# nrf9220_celldsp register map
Vendor: Nordic Semiconductor; Series: nRF92; File version: 1
Registers are 32-bit, read-write, reset 0x0 unless marked. A register's access mark holds for its fields unless they carry their own. Offsets are from the block's base; [hi:lo] are bit positions; {n}, {i} and the like mark numbered series.

## TRACEDELAYREG — Trace delay register
Base 0x45027000
0x504 DELAYREGCONFIG — Configuration register for DELAYREG delay
  [4:0] DELAYREGCONFIG — Register write delay, configurable between 0 and 31 clock cycles. Delay between apbPEnable and apbPReady is adjusted to the configured value, except for the small values, when minimum interconnect delay exist.
0x600 DELAYREG wo — Dummy register with adjustable write delay. Occupies 0x100 address range i.e. 256bytes. This space emulates the extended stimulus port area of ARM Coresight STM.
  [31:0] DELAYREG — Dummy register with adjustable write delay

## BELLBOARD — BELLBOARD APB registers
Base 0x4F09D000
{0x0+4i} TASKS_TRIGGER[{i}] (i=0..31) wo — Description collection: Task TRIGGER[n]
  [0] TASKS_TRIGGER — Task TRIGGER[n]
    1=Trigger task
{0x100+4i} EVENTS_TRIGGERED[{i}] (i=0..31) — Description collection: Event TRIGGERED[n]
  [0] EVENTS_TRIGGERED — Event TRIGGERED[n]
    0=NotGenerated (Event not generated); 1=Generated (Event generated)
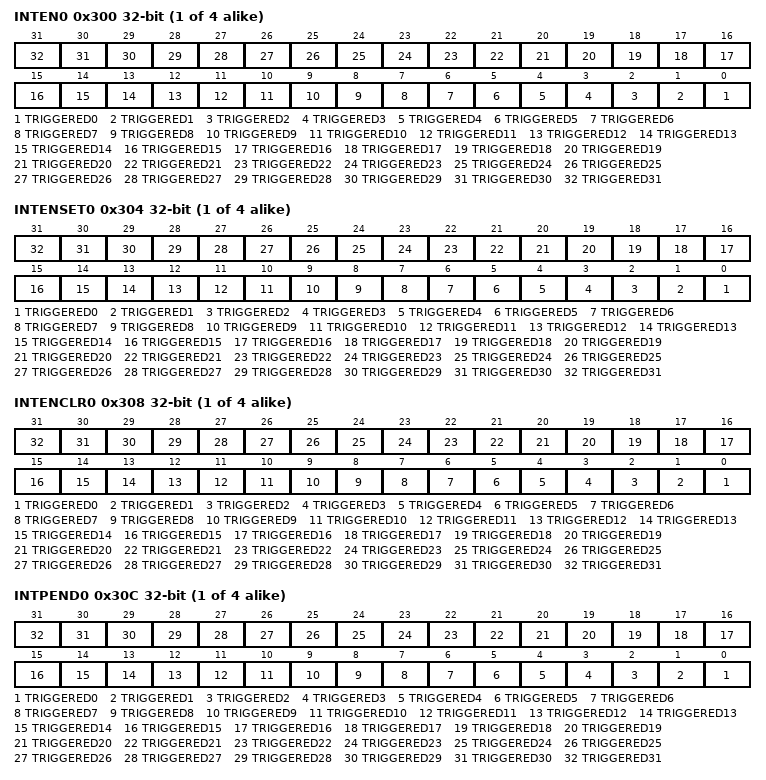
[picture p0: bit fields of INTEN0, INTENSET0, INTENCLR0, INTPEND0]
{0x300+0x10*i} INTEN{i} (i=0..3) — Enable or disable interrupt
  [all] fields
    0=Disabled; 1=Enabled
  [n] TRIGGERED{n} (n=0..31) — Enable or disable interrupt for event TRIGGERED[{n}]
{0x304+0x10*i} INTENSET{i} (i=0..3) — Enable interrupt
  [all] fields
    on read: 0=Disabled (Read: Disabled); 1=Enabled (Read: Enabled) | on write: 1=Set (Enable)
  [n] TRIGGERED{n} (n=0..31) — Write '1' to enable interrupt for event TRIGGERED[{n}]
{0x308+0x10*i} INTENCLR{i} (i=0..3) — Disable interrupt
  [all] fields
    on read: 0=Disabled (Read: Disabled); 1=Enabled (Read: Enabled) | on write: 1=Clear (Disable)
  [n] TRIGGERED{n} (n=0..31) — Write '1' to disable interrupt for event TRIGGERED[{n}]
{0x30C+0x10*i} INTPEND{i} ro (i=0..3) — Pending interrupts
  [all] fields
    on read: 0=NotPending (Read: Not pending); 1=Pending (Read: Pending)
  [n] TRIGGERED{n} (n=0..31) — Read pending status of interrupt for event TRIGGERED[{n}]

## GLOBAL_MUTEX120 — MUTEX 0
Base 0x4F8D2000
Same registers: GLOBAL_MUTEX130 0x4F927000
{0x400+4i} MUTEX[{i}] (i=0..31) — Description collection: Mutex register
  [0] MUTEX — Mutex register n
    0=Unlocked (Mutex n is in unlocked state); 1=Locked (Mutex n is in locked state)

## GLOBAL_PROTOTYPE — Prototype HW information registers.
Base 0x4F8D2000; alternate view of GLOBAL_MUTEX120
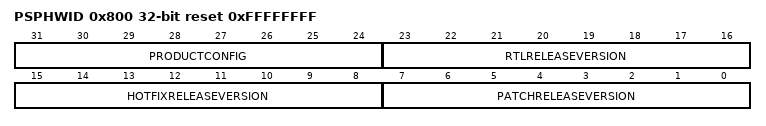
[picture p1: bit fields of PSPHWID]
0x800 PSPHWID ro reset 0xFFFFFFFF — PSP hardware ID register, unique ID for each prototype release. Used to identify RTL release that prototype is based on.
  [31:24] PRODUCTCONFIG
  [23:16] RTLRELEASEVERSION — First letter of RTL release version in ASCII corresponding to A-Z.
  [15:8] HOTFIXRELEASEVERSION
  [7:0] PATCHRELEASEVERSION — PSP patch/bugfix release version
0x804 FPGATIMESTAMP ro — 32-bit timestamp value stored by the FPGA bitstream in format ddddd_MMMM_yyyyyy_hhhhh_mmmmmm_ssssss. Unique for every FPGA netlist implementation, not dependent to RTL synthesis. 0x87654321 set in emulator database.
  [31:0] FPGATIMESTAMP — ddddd = 5 bits to represent 31 days in a month. MMMM = 4 bits to represent 12 months in a year. yyyyyy = 6 bits to represent 0 to 63 (to note year 2000 to 2063). hhhhh = 5 bits to represent 24 hours in a day. mmmmmm = 6 bits to represent 60 minutes in an hour. ssssss = 6 bits to represent 60 seconds in a minute.
0x808 EMULATORSPEEDVALUE ro — Used to store real speed of emulator is running. Used by SW to config UART speed etc, to ensure correct operation.
  [31:0] EMULATORSPEEDVALUE — Actual clock speed for FCLK 400M in emulator (Hz). In FPGA set to 0x0.
0x80C FPGACLOCKDIVIDERRATIO ro — Overall clock divider ratio for FPGA
  [31:0] FPGACLOCKDIVIDERRATIO — Overall clock divider ratio for FPGA. Set to 0 for emulator database.
